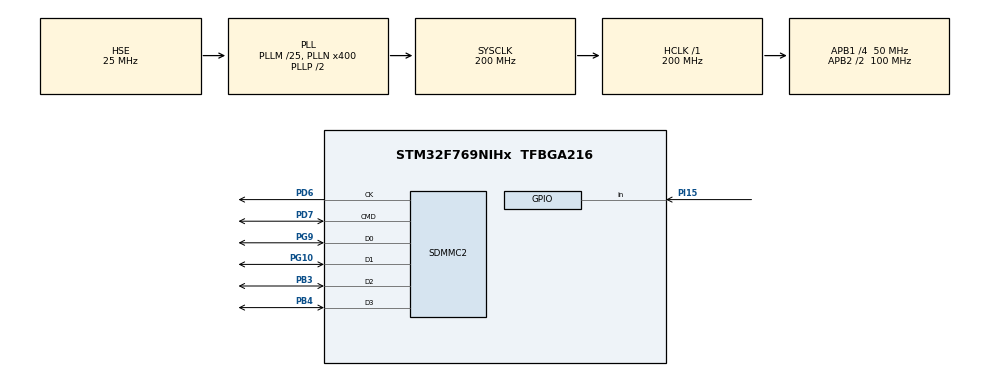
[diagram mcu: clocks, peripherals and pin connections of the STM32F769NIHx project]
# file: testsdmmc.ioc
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Dma.Request0=SDMMC2_RX
Dma.Request1=SDMMC2_TX
Dma.SDMMC2_RX.0.Direction=DMA_PERIPH_TO_MEMORY
Dma.SDMMC2_RX.0.FIFOMode=DMA_FIFOMODE_ENABLE
Dma.SDMMC2_RX.0.FIFOThreshold=DMA_FIFO_THRESHOLD_FULL
Dma.SDMMC2_RX.0.Instance=DMA2_Stream0
Dma.SDMMC2_RX.0.MemBurst=DMA_MBURST_INC4
Dma.SDMMC2_RX.0.MemDataAlignment=DMA_MDATAALIGN_WORD
Dma.SDMMC2_RX.0.MemInc=DMA_MINC_ENABLE
Dma.SDMMC2_RX.0.Mode=DMA_PFCTRL
Dma.SDMMC2_RX.0.PeriphBurst=DMA_PBURST_INC4
Dma.SDMMC2_RX.0.PeriphDataAlignment=DMA_PDATAALIGN_WORD
Dma.SDMMC2_RX.0.PeriphInc=DMA_PINC_DISABLE
Dma.SDMMC2_RX.0.Priority=DMA_PRIORITY_LOW
Dma.SDMMC2_TX.1.Direction=DMA_MEMORY_TO_PERIPH
Dma.SDMMC2_TX.1.FIFOMode=DMA_FIFOMODE_ENABLE
Dma.SDMMC2_TX.1.FIFOThreshold=DMA_FIFO_THRESHOLD_FULL
Dma.SDMMC2_TX.1.Instance=DMA2_Stream5
Dma.SDMMC2_TX.1.MemBurst=DMA_MBURST_INC4
Dma.SDMMC2_TX.1.MemDataAlignment=DMA_MDATAALIGN_WORD
Dma.SDMMC2_TX.1.MemInc=DMA_MINC_ENABLE
Dma.SDMMC2_TX.1.Mode=DMA_PFCTRL
Dma.SDMMC2_TX.1.PeriphBurst=DMA_PBURST_INC4
Dma.SDMMC2_TX.1.PeriphDataAlignment=DMA_PDATAALIGN_WORD
Dma.SDMMC2_TX.1.PeriphInc=DMA_PINC_DISABLE
Dma.SDMMC2_TX.1.Priority=DMA_PRIORITY_LOW
FATFS.BSP.number=1
FATFS.USE_DMA_CODE_SD=1
FATFS0.BSP.STBoard=false
FATFS0.BSP.api=Unknown
FATFS0.BSP.instance=PI15
FATFS0.BSP.ip=GPIO
FATFS0.BSP.mode=Input
FATFS0.BSP.name=Detect_SDIO
FATFS0.BSP.solution=PI15
Mcu.Family=STM32F7
Mcu.Name=STM32F769NIHx
Mcu.Package=TFBGA216
NVIC.DMA2_Stream0_IRQn=true\:0\:0\:false\:false\:true\:false\:true\:true
NVIC.DMA2_Stream5_IRQn=true\:0\:0\:false\:false\:true\:false\:true\:true
NVIC.PriorityGroup=NVIC_PRIORITYGROUP_4
PB3.Mode=SD_4_bits_Wide_bus
PB3.Signal=SDMMC2_D2
PB4.Mode=SD_4_bits_Wide_bus
PB4.Signal=SDMMC2_D3
PD6.Mode=SD_4_bits_Wide_bus
PD6.Signal=SDMMC2_CK
PD7.Mode=SD_4_bits_Wide_bus
PD7.Signal=SDMMC2_CMD
PG10.Mode=SD_4_bits_Wide_bus
PG10.Signal=SDMMC2_D1
PG9.Mode=SD_4_bits_Wide_bus
PG9.Signal=SDMMC2_D0
PH0/OSC_IN.Mode=HSE-External-Oscillator
PH0/OSC_IN.Signal=RCC_OSC_IN
PH1/OSC_OUT.Mode=HSE-External-Oscillator
PH1/OSC_OUT.Signal=RCC_OSC_OUT
PI15.Signal=GPIO_Input
ProjectManager.HeapSize=0x200
ProjectManager.StackSize=0x400
ProjectManager.TargetToolchain=STM32CubeIDE
RCC.AHBFreq_Value=200000000
RCC.APB1CLKDivider=RCC_HCLK_DIV4
RCC.APB1Freq_Value=50000000
RCC.APB1TimFreq_Value=100000000
RCC.APB2CLKDivider=RCC_HCLK_DIV2
RCC.APB2Freq_Value=100000000
RCC.APB2TimFreq_Value=200000000
RCC.CortexFreq_Value=200000000
RCC.HCLKFreq_Value=200000000
RCC.HSE_VALUE=25000000
RCC.HSI_VALUE=16000000
RCC.LSE_VALUE=32768
RCC.PLLM=25
RCC.PLLN=400
RCC.PLLQ=8
RCC.PLLSourceVirtual=RCC_PLLSOURCE_HSE
RCC.SDMMC2ClockSelection=RCC_SDMMC2CLKSOURCE_CLK48
RCC.SYSCLKFreq_VALUE=200000000
RCC.SYSCLKSource=RCC_SYSCLKSOURCE_PLLCLK
RCC.USBFreq_Value=50000000
RCC.VCOOutputFreq_Value=400000000
VP_FATFS_VS_SDIO.Mode=SDIO
board=custom

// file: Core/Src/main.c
/* USER CODE BEGIN Header */
/**
  ******************************************************************************
  * @file           : main.c
  * @brief          : Main program body
  ******************************************************************************
  * @attention
  *
  * Copyright (c) 2025 STMicroelectronics.
  * All rights reserved.
  *
  * This software is licensed under terms that can be found in the LICENSE file
  * in the root directory of this software component.
  * If no LICENSE file comes with this software, it is provided AS-IS.
  *
  ******************************************************************************
  */
/* USER CODE END Header */
#include "main.h"
#include "fatfs.h"
#include <string.h>

SD_HandleTypeDef hsd2;
DMA_HandleTypeDef hdma_sdmmc2_rx;
DMA_HandleTypeDef hdma_sdmmc2_tx;

/* USER CODE BEGIN PV */

FRESULT res; /* FatFs function common result code */
uint32_t byteswritten, bytesread; /* File write/read counts */
uint8_t wtext[] = "STM32 FATFS works great!"; /* File write buffer */
uint8_t rtext[_MAX_SS];/* File read buffer *//* USER CODE BEGIN Header */

/* USER CODE END PV */

void SystemClock_Config(void);
static void MX_GPIO_Init(void);
static void MX_DMA_Init(void);
static void MX_SDMMC2_SD_Init(void);

int main(void)
{

  /* MCU Configuration--------------------------------------------------------*/

  /* Reset of all peripherals, Initializes the Flash interface and the Systick. */
  HAL_Init();

  /* Configure the system clock */
  SystemClock_Config();

  /* Initialize all configured peripherals */
  MX_GPIO_Init();
  MX_DMA_Init();
  MX_SDMMC2_SD_Init();
  MX_FATFS_Init();

  /* Infinite loop */
  while (1)
  {
		if(f_mount(&SDFatFS, (TCHAR const*)SDPath, 0) != FR_OK)
		{
			Error_Handler();
		}
		else
		{
			if(f_mkfs((TCHAR const*)SDPath, FM_ANY, 0, rtext, sizeof(rtext)) != FR_OK)
		    {
				Error_Handler();
		    }
			else
			{
				//Open file for writing (Create)
				if(f_open(&SDFile, "STM32.TXT", FA_CREATE_ALWAYS | FA_WRITE) != FR_OK)
				{
					Error_Handler();
				}
				else
				{

					//Write to the text file
					res = f_write(&SDFile, wtext, strlen((char *)wtext), (void *)&byteswritten);
					if((byteswritten == 0) || (res != FR_OK))
					{
						Error_Handler();
					}
					else
					{

						f_close(&SDFile);
					}
				}
			}
		}
		f_mount(&SDFatFS, (TCHAR const*)NULL, 0);

  }
}

void SystemClock_Config(void)
{
  RCC_OscInitTypeDef RCC_OscInitStruct = {0};
  RCC_ClkInitTypeDef RCC_ClkInitStruct = {0};

  /** Configure the main internal regulator output voltage
  */
  __HAL_RCC_PWR_CLK_ENABLE();
  __HAL_PWR_VOLTAGESCALING_CONFIG(PWR_REGULATOR_VOLTAGE_SCALE1);

  /** Initializes the RCC Oscillators according to the specified parameters
  * in the RCC_OscInitTypeDef structure.
  */
  RCC_OscInitStruct.OscillatorType = RCC_OSCILLATORTYPE_HSE;
  RCC_OscInitStruct.HSEState = RCC_HSE_ON;
  RCC_OscInitStruct.PLL.PLLState = RCC_PLL_ON;
  RCC_OscInitStruct.PLL.PLLSource = RCC_PLLSOURCE_HSE;
  RCC_OscInitStruct.PLL.PLLM = 25;
  RCC_OscInitStruct.PLL.PLLN = 400;
  RCC_OscInitStruct.PLL.PLLP = RCC_PLLP_DIV2;
  RCC_OscInitStruct.PLL.PLLQ = 8;
  RCC_OscInitStruct.PLL.PLLR = 2;
  if (HAL_RCC_OscConfig(&RCC_OscInitStruct) != HAL_OK)
  {
    Error_Handler();
  }

  /** Activate the Over-Drive mode
  */
  if (HAL_PWREx_EnableOverDrive() != HAL_OK)
  {
    Error_Handler();
  }

  /** Initializes the CPU, AHB and APB buses clocks
  */
  RCC_ClkInitStruct.ClockType = RCC_CLOCKTYPE_HCLK|RCC_CLOCKTYPE_SYSCLK
                              |RCC_CLOCKTYPE_PCLK1|RCC_CLOCKTYPE_PCLK2;
  RCC_ClkInitStruct.SYSCLKSource = RCC_SYSCLKSOURCE_PLLCLK;
  RCC_ClkInitStruct.AHBCLKDivider = RCC_SYSCLK_DIV1;
  RCC_ClkInitStruct.APB1CLKDivider = RCC_HCLK_DIV4;
  RCC_ClkInitStruct.APB2CLKDivider = RCC_HCLK_DIV2;

  if (HAL_RCC_ClockConfig(&RCC_ClkInitStruct, FLASH_LATENCY_6) != HAL_OK)
  {
    Error_Handler();
  }
}

static void MX_SDMMC2_SD_Init(void)
{

  hsd2.Instance = SDMMC2;
  hsd2.Init.ClockEdge = SDMMC_CLOCK_EDGE_RISING;
  hsd2.Init.ClockBypass = SDMMC_CLOCK_BYPASS_DISABLE;
  hsd2.Init.ClockPowerSave = SDMMC_CLOCK_POWER_SAVE_DISABLE;
  hsd2.Init.BusWide = SDMMC_BUS_WIDE_4B;
  hsd2.Init.HardwareFlowControl = SDMMC_HARDWARE_FLOW_CONTROL_DISABLE;
  hsd2.Init.ClockDiv = 0;

}

static void MX_DMA_Init(void)
{

  /* DMA controller clock enable */
  __HAL_RCC_DMA2_CLK_ENABLE();

  /* DMA interrupt init */
  /* DMA2_Stream0_IRQn interrupt configuration */
  HAL_NVIC_SetPriority(DMA2_Stream0_IRQn, 0, 0);
  HAL_NVIC_EnableIRQ(DMA2_Stream0_IRQn);
  /* DMA2_Stream5_IRQn interrupt configuration */
  HAL_NVIC_SetPriority(DMA2_Stream5_IRQn, 0, 0);
  HAL_NVIC_EnableIRQ(DMA2_Stream5_IRQn);

}

static void MX_GPIO_Init(void)
{
  GPIO_InitTypeDef GPIO_InitStruct = {0};

  /* GPIO Ports Clock Enable */
  __HAL_RCC_GPIOB_CLK_ENABLE();
  __HAL_RCC_GPIOD_CLK_ENABLE();
  __HAL_RCC_GPIOG_CLK_ENABLE();
  __HAL_RCC_GPIOH_CLK_ENABLE();
  __HAL_RCC_GPIOI_CLK_ENABLE();

  /*Configure GPIO pin : PI15 */
  GPIO_InitStruct.Pin = GPIO_PIN_15;
  GPIO_InitStruct.Mode = GPIO_MODE_INPUT;
  GPIO_InitStruct.Pull = GPIO_NOPULL;
  HAL_GPIO_Init(GPIOI, &GPIO_InitStruct);

}

void Error_Handler(void)
{
  __disable_irq();
  while (1)
  {
  }
}
